AUTOSAR XML (schema 4-3-0)
package /ComponentTypes
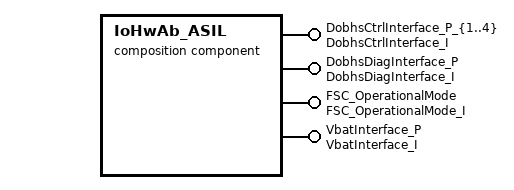
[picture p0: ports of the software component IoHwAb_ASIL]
  composition sw component type IoHwAb_ASIL
    7 x provide port:
      DobhsCtrlInterface_P_{1..4}: provided-interface=DobhsCtrlInterface_I
      DobhsDiagInterface_P: server-com-spec{operation=IoHwAbOperation, queue-length=1}, provided-interface=DobhsDiagInterface_I
      FSC_OperationalMode: provided-com-specs=[{operation=FSC_OperationalMode, queue-length=1}, {operation=VbatInterface_P, queue-length=1}], provided-interface=FSC_OperationalMode_I
      VbatInterface_P: provided-interface=VbatInterface_I
        provided-com-specs:
          operation=DobhsCtrlInterface_P_4, queue-length=1
          operation=DobhsCtrlInterface_P_5, queue-length=1
          operation=DobhsCtrlInterface_P_3, queue-length=1
          operation=DobhsCtrlInterface_P_2, queue-length=1
          operation=DobhsCtrlInterface_P_1, queue-length=1
          operation=FSC_OperationalMode, queue-length=1
          operation=VbatInterface_P, queue-length=1
    component CoreHW_ASIL: type=IoHwAb_ASIL_Core
    component IoHwAb_ASIL_Dobhs: type=IoHwAb_ASIL_Dobhs
    connect CoreHW_ASIL.VbatInterface_P -> IoHwAb_ASIL_Dobhs.VbatInterface_P
    connect CoreHW_ASIL.FSC_OperationalMode -> IoHwAb_ASIL_Dobhs.FSC_OperationalMode
    delegate CoreHW_ASIL.FSC_OperationalMode <-> outer port FSC_OperationalMode
    delegate IoHwAb_ASIL_Dobhs.DobhsCtrlInterface_P_3 <-> outer port DobhsCtrlInterface_P_3
    delegate IoHwAb_ASIL_Dobhs.DobhsDiagInterface_P <-> outer port DobhsDiagInterface_P
    delegate IoHwAb_ASIL_Dobhs.DobhsCtrlInterface_P_4 <-> outer port DobhsCtrlInterface_P_4
    delegate CoreHW_ASIL.VbatInterface_P <-> outer port VbatInterface_P
    delegate IoHwAb_ASIL_Dobhs.DobhsCtrlInterface_P_1 <-> outer port DobhsCtrlInterface_P_1
    delegate IoHwAb_ASIL_Dobhs.DobhsCtrlInterface_P_2 <-> outer port DobhsCtrlInterface_P_2
